# L4_PER1_IA_IP0 register map
Vendor: Texas Instruments
Peripheral module from a debugger description file (folder TDA3x).
Registers are 32-bit, read-only, reset 0x0 unless marked. A register's access mark holds for its fields unless they carry their own. Offsets are as the file gives them; lines under a group give offsets from that group; [hi:lo] are bit positions; {n}, {i} and the like mark numbered series; 'fields as' and 'values as' point back to an identical list; <NAME> marks a mode.

## L4_PER1_IA_IP0
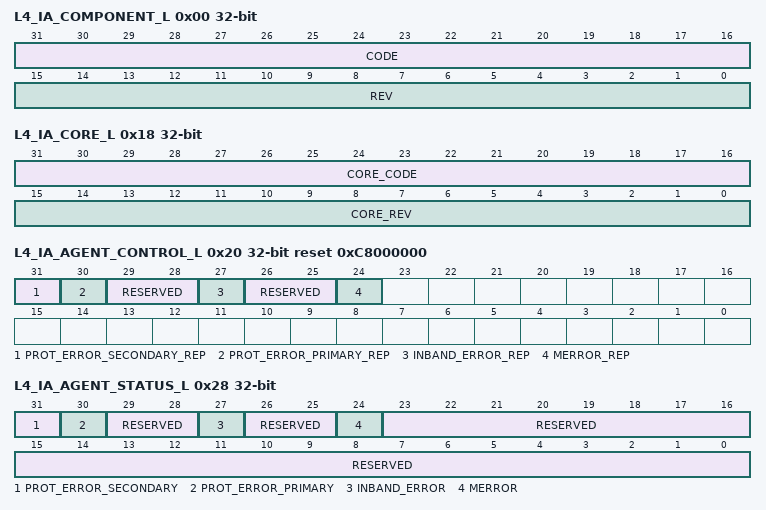
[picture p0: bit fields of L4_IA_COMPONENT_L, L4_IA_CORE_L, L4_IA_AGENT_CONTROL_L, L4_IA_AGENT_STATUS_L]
0x00 L4_IA_COMPONENT_L reset not defined — COMPONENT register identifies the component to which this register block belongs. The register contains a component code and revision, which are used to identify the hardware of the component. The COMPONENT register is read-only.
  [31:16] CODE — Interconnect code
  [15:0] REV — Component revision code
0x04 L4_IA_COMPONENT_H — COMPONENT register identifies the component to which this register block belongs. The register contains a component code and revision, which are used to identify the hardware of the component. The COMPONENT register is read-only.
  [31:0] RESERVED — Read returns 0.
0x18 L4_IA_CORE_L reset not defined — Provide information about the core initiator
  [31:16] CORE_CODE — Interconnect core code
  [15:0] CORE_REV — Component revision code code
0x1C L4_IA_CORE_H (reset mask 0xFFFF0000) — Provide information about the core initiator
  [15:0] VENDOR_CODE — Vendor revision core code
0x20 L4_IA_AGENT_CONTROL_L access per field reset 0xC8000000 — Core control for an initiator OCP interface
  [31] PROT_ERROR_SECONDARY_REP rw — Out-of-band reporting of protection mechanism secondary errors
  [30] PROT_ERROR_PRIMARY_REP rw — Out-of-band reporting of protection mechanism primary errors
  [29:28] RESERVED ro — Read returns 0.
  [27] INBAND_ERROR_REP rw — Setting this field to 1 reports on in-band errors using the INBAND_ERROR log bit of IA.AGENT_STATUS register. The error reporting mechanism is enabled when the INBAND_ERROR_REP bit field is set to 1.
  [26:25] RESERVED ro — Read returns 0.
  [24] MERROR_REP ro — OCP MError reporting control. The out-of-band OCP MError reporting mechanism is enabled when the MERROR_REP bit field is set to 1.
0x24 L4_IA_AGENT_CONTROL_H — Enable error reporting on an initiator interface.
  [31:0] RESERVED — Read returns 0.
0x28 L4_IA_AGENT_STATUS_L access not given — Stores status information for an initiator. The INBAND_ERROR and MERROR fields are read/write and are implemented as log bits.
  [31] PROT_ERROR_SECONDARY — 0x0: Secondary Protection error not present.0x1: Secondary Protection error present (access RW W1toClr)
  [30] PROT_ERROR_PRIMARY — 0x0: Primary Protection error not present.0x1: Primary Protection error present (access RW W1toClr)
  [29:28] RESERVED ro — Read returns 0.
  [27] INBAND_ERROR — 0x0 No In-Band error present.0x1 In-Band error present. (access RW W1toClr)
  [26:25] RESERVED ro — Read returns 0.
  [24] MERROR ro — Value of the OCP MError signal
  [23:0] RESERVED ro — Read returns 0
0x2C L4_IA_AGENT_STATUS_H — Stores status information for an initiator.
  [31:0] RESERVED — Read returns 0.
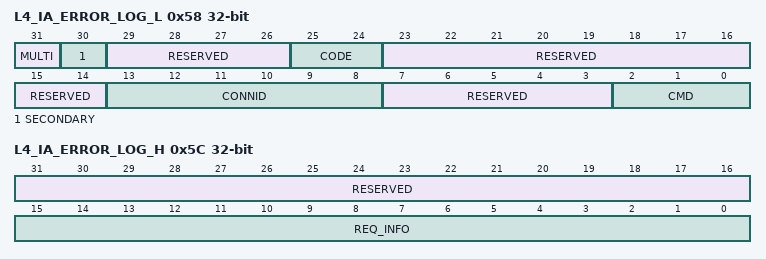
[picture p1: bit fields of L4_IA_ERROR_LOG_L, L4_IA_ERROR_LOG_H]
0x58 L4_IA_ERROR_LOG_L access not given — Log information about error conditions. The CODE field logs any protection violation or address hole errors detected by the initiator subsystem while decoding a request.
  [31] MULTI — Multiple errors detected (access RW W1toClr)
  [30] SECONDARY — Indicates whether protection violation was a primary or secondary error (access RW W1toClr)
  [29:26] RESERVED ro — Read returns 0.
  [25:24] CODE — The error code of an initiator request. 0x0: No errors 0x1: Unsupported command 0x2: Address hole 0x3: Protection violation (access RW W1toClr)
  [23:14] RESERVED ro — Read returns 0.
  [13:8] CONNID ro — ConnID of request causing the error, refer to
  [7:3] RESERVED ro — Read returns 0.
  [2:0] CMD ro — Command that has caused an error.
0x5C L4_IA_ERROR_LOG_H — Log information about error conditions.
  [31:16] RESERVED — Read returns 0.
  [15:0] REQ_INFO — MReqInfo bits of request that has caused the error REQ_INFO[0] = supervisor, REQ_INFO[1] = Debug
0x60 L4_IA_ERROR_LOG_ADDR_L — Extended error log (address information)
  [31:0] ADDR — Address of request that has caused the error. N is the number MAddr bits.
0x64 L4_IA_ERROR_LOG_ADDR_H — Extended error log (address information)
  [31:0] RESERVED — Read returns 0.
